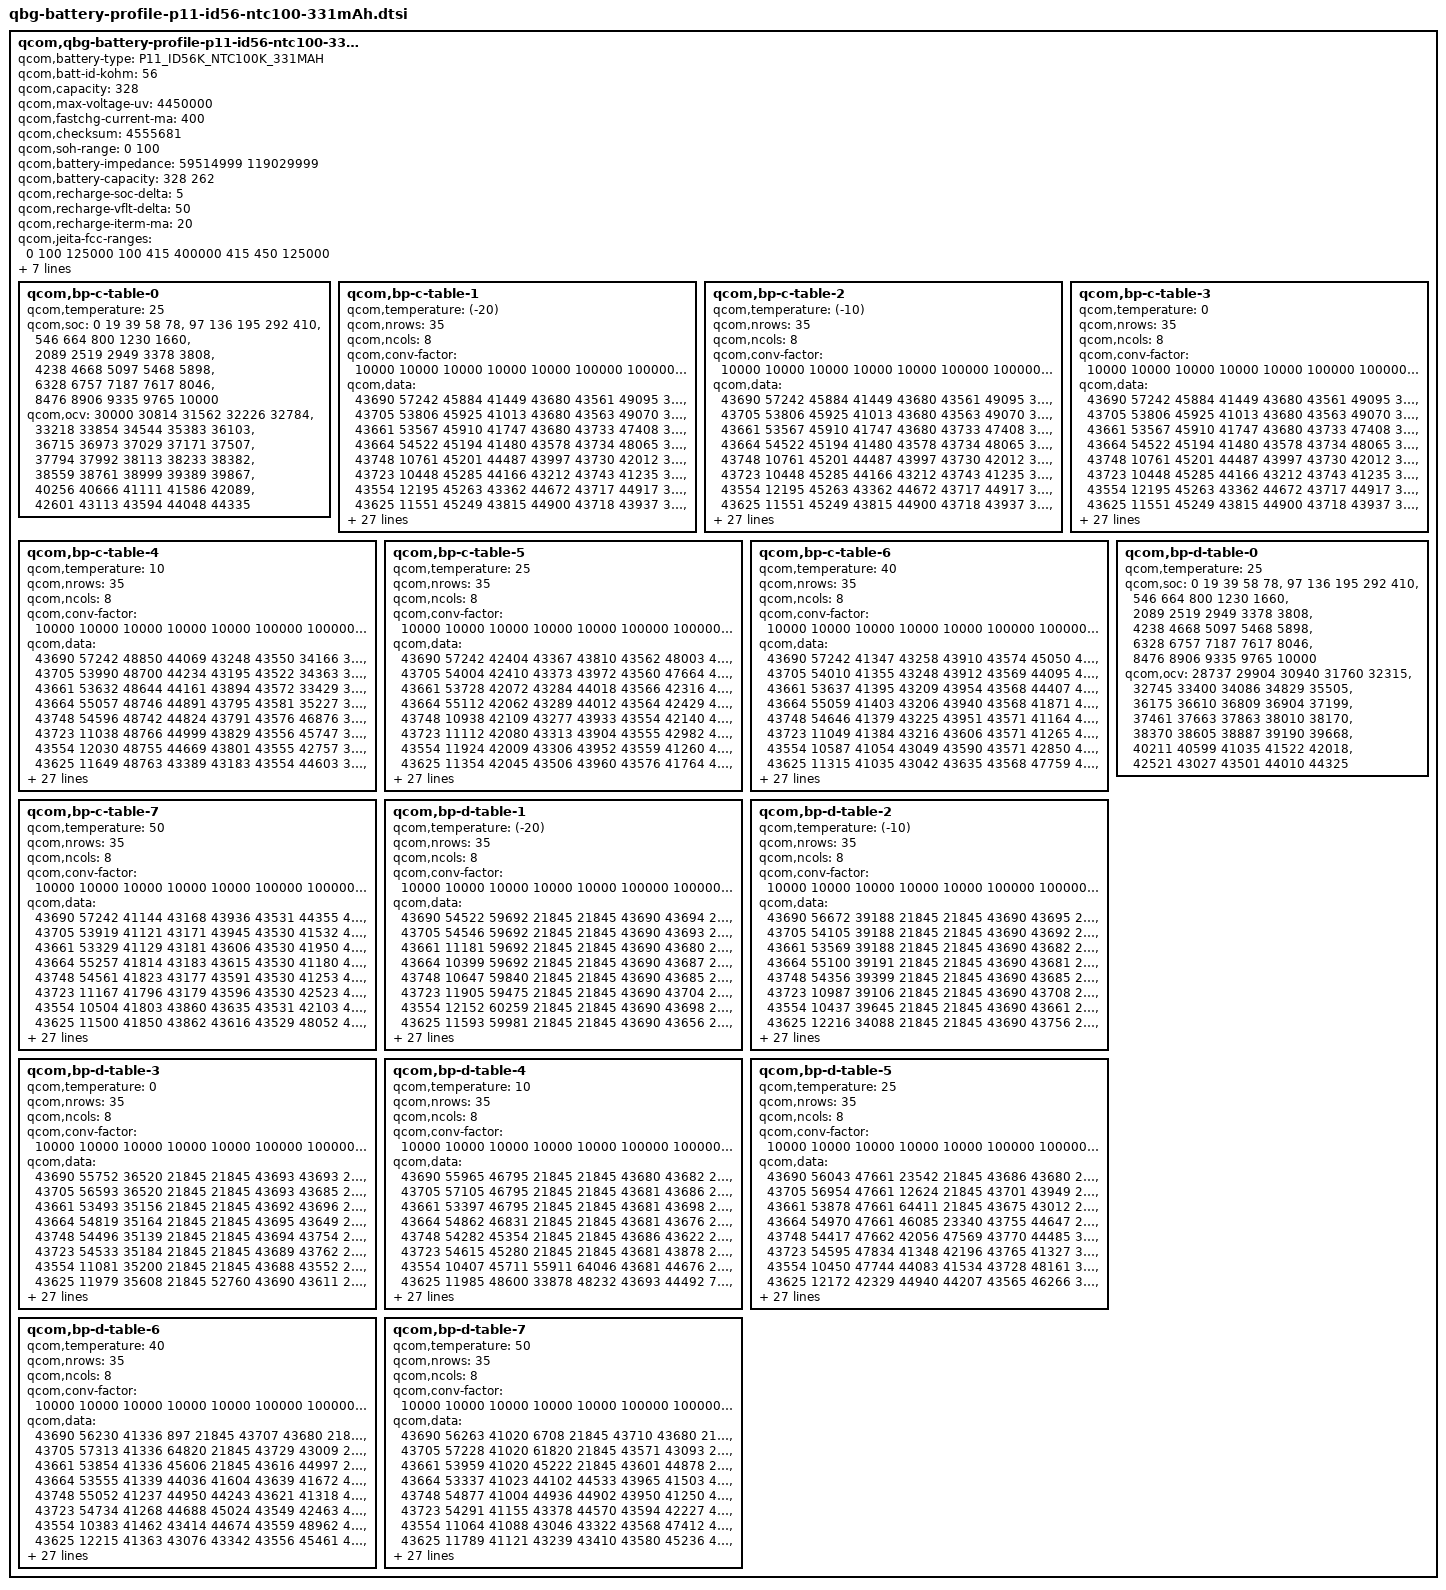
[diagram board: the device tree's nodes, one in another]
// SPDX-License-Identifier: GPL-2.0

/*QBG Profiling Rev. 2.7*/

qcom,qbg-battery-profile-p11-id56-ntc100-331mAh {
	qcom,battery-type = "P11_ID56K_NTC100K_331MAH";
	qcom,batt-id-kohm = <56>;
	/* 331 is the capacity of the cell, the minimum capacity is 328 mAh because
	of losing some usable capacity by PCM */
	qcom,capacity = <328>;

	qcom,max-voltage-uv = <4450000>;
	qcom,fastchg-current-ma = <400>;
	/*@5, 0.005V, 4% */
	qcom,checksum = <4555681>;
	qcom,soh-range = <0 100>;
	/* Nominal_Impedance in 10nohm @ SOC 50% 25C* 0:fresh cell, 1: aged cell */
	qcom,battery-impedance = <59514999 119029999>;
	/* Nominal_Capacity in mAh. 0: fresh cell, 1:aged cell */
	/* 100% 80% */
	qcom,battery-capacity = <328 262>;
	/* SOC delta (in percent) dropped from EOC SOC to enable recharge */
	qcom,recharge-soc-delta =<5>;
	/* vfloat delta (in mV) dropped from regular vfloat in recharge */
	qcom,recharge-vflt-delta =<50>;
	/* termination current (in mA) in recharge */
	qcom,recharge-iterm-ma = <20>;
	/* LowTemp HighTemp CharingCurrent (uA) */
	qcom,jeita-fcc-ranges = <0  100 125000
				100 415 400000
				415 450 125000>;

	qcom,jeita-fv-ranges = <0   100 4450000
				100 415 4450000
				415 450 4450000>;

	/* COOL = 10 DegC, WARM = 41.5 DegC */
	qcom,jeita-soft-thresholds = <0x2b8a 0x1491>;
	/* COLD = 0 DegC, HOT = 45 DegC */
	qcom,jeita-hard-thresholds = <0x3257 0x128c>;
	/* COOL = 12 DegC, WARM = 39.5 DegC*/
	qcom,jeita-soft-hys-thresholds = <0x2a0b 0x15ca>;
	qcom,jeita-soft-fcc-ua = <125000 125000>;
	qcom,jeita-soft-fv-uv = <4450000 4450000>;

	qcom,bp-c-table-0 {
		qcom,temperature = <25>;
		qcom,soc = <    0    19    39    58    78>,
			<   97   136   195   292   410>,
			<  546   664   800  1230  1660>,
			< 2089  2519  2949  3378  3808>,
			< 4238  4668  5097  5468  5898>,
			< 6328  6757  7187  7617  8046>,
			< 8476  8906  9335  9765 10000>;
		qcom,ocv = <30000 30814 31562 32226 32784>,
			<33218 33854 34544 35383 36103>,
			<36715 36973 37029 37171 37507>,
			<37794 37992 38113 38233 38382>,
			<38559 38761 38999 39389 39867>,
			<40256 40666 41111 41586 42089>,
			<42601 43113 43594 44048 44335>;
	};
	qcom,bp-c-table-1 {
		qcom,temperature = <(-20)>;
		qcom,nrows = <35>;
		qcom,ncols = <8>;
		qcom,conv-factor = <10000 10000 10000 10000 10000 100000 100000 10000>;
		qcom,data = <43690 57242 45884 41449 43680 43561 49095 39200>,
			<43705 53806 45925 41013 43680 43563 49070 38997>,
			<43661 53567 45910 41747 43680 43733 47408 39105>,
			<43664 54522 45194 41480 43578 43734 48065 39800>,
			<43748 10761 45201 44487 43997 43730 42012 39827>,
			<43723 10448 45285 44166 43212 43743 41235 39432>,
			<43554 12195 45263 43362 44672 43717 44917 34086>,
			<43625 11551 45249 43815 44900 43718 43937 33994>,
			<43918  8286 45242 43547 44237 43742 43623 34770>,
			<43824 10002 45907 43838 44998 43556 43955 34428>,
			<43144 15012 45243 43543 44885 43577 43637 34435>,
			<43058 14969 45939 44010 45012 43531 43950 33148>,
			<43402 15271 45897 43789 44929 43530 43909 33028>,
			<44644 15135 45937 44387 43171 43553 47659 33975>,
			<44246 14759 45184 41786 43134 43729 47879 34058>,
			<41603 16030 45478 41114 43465 43731 48066 34120>,
			<41853 16299 45876 40986 43291 43730 47836 39585>,
			<41263 16328 46057 41378 43355 43741 47741 39570>,
			<42904 16236 46057 41466 44682 43743 47794 39469>,
			<42058 15509 46024 41258 44749 43737 41993 39514>,
			<47652 15470 46075 41318 44655 43739 42381 39891>,
			<47254 15856 46055 42727 44625 43736 47587 39098>,
			<47427 13051 46066 42558 44553 43737 48295 39796>,
			<49142 13073 46030 42554 43283 43736 48821 39502>,
			<48544 12746 46045 42628 44678 43713 44380 39830>,
			<45586 13853 45220 42998 44544 43724 41562 39183>,
			<45263 13567 45089 42877 44989 43720 44424 40756>,
			<46777 13650 45448 42193 44902 43765 44193 37536>,
			<46955  2820 45318 42405 44117 43765 44952 37284>,
			<46532  2350 46774 42481 41545 43765 44683 37912>,
			<35766  4036 46624 42273 41323 43720 43506 59866>,
			<34912  3535 47011 42345 47786 43727 43109 57510>,
			<36573  1023 46969 42445 48610 43715 43258 63817>,
			<35983   433 46933 42825 36753 43721 43890 51539>,
			<36282  1773 46140 44923 47301 43617 43647 59129>;
	};
	qcom,bp-c-table-2 {
		qcom,temperature = <(-10)>;
		qcom,nrows = <35>;
		qcom,ncols = <8>;
		qcom,conv-factor = <10000 10000 10000 10000 10000 100000 100000 10000>;
		qcom,data = <43690 57242 45884 41449 43680 43561 49095 39200>,
			<43705 53806 45925 41013 43680 43563 49070 38997>,
			<43661 53567 45910 41747 43680 43733 47408 39105>,
			<43664 54522 45194 41480 43578 43734 48065 39800>,
			<43748 10761 45201 44487 43997 43730 42012 39827>,
			<43723 10448 45285 44166 43212 43743 41235 39432>,
			<43554 12195 45263 43362 44672 43717 44917 34086>,
			<43625 11551 45249 43815 44900 43718 43937 33994>,
			<43918  8286 45242 43547 44237 43742 43623 34770>,
			<43824 10002 45907 43838 44998 43556 43955 34428>,
			<43144 15012 45243 43543 44885 43577 43637 34435>,
			<43058 14969 45939 44010 45012 43531 43950 33148>,
			<43402 15271 45897 43789 44929 43530 43909 33028>,
			<44644 15135 45937 44387 43171 43553 47659 33975>,
			<44246 14759 45184 41786 43134 43729 47879 34058>,
			<41603 16030 45478 41114 43465 43731 48066 34120>,
			<41853 16299 45876 40986 43291 43730 47836 39585>,
			<41263 16328 46057 41378 43355 43741 47741 39570>,
			<42904 16236 46057 41466 44682 43743 47794 39469>,
			<42058 15509 46024 41258 44749 43737 41993 39514>,
			<47652 15470 46075 41318 44655 43739 42381 39891>,
			<47254 15856 46055 42727 44625 43736 47587 39098>,
			<47427 13051 46066 42558 44553 43737 48295 39796>,
			<49142 13073 46030 42554 43283 43736 48821 39502>,
			<48544 12746 46045 42628 44678 43713 44380 39830>,
			<45586 13853 45220 42998 44544 43724 41562 39183>,
			<45263 13567 45089 42877 44989 43720 44424 40756>,
			<46777 13650 45448 42193 44902 43765 44193 37536>,
			<46955  2820 45318 42405 44117 43765 44952 37284>,
			<46532  2350 46774 42481 41545 43765 44683 37912>,
			<35766  4036 46624 42273 41323 43720 43506 59866>,
			<34912  3535 47011 42345 47786 43727 43109 57510>,
			<36573  1023 46969 42445 48610 43715 43258 63817>,
			<35983   433 46933 42825 36753 43721 43890 51539>,
			<36282  1773 46140 44923 47301 43617 43647 59129>;
	};
	qcom,bp-c-table-3 {
		qcom,temperature = <0>;
		qcom,nrows = <35>;
		qcom,ncols = <8>;
		qcom,conv-factor = <10000 10000 10000 10000 10000 100000 100000 10000>;
		qcom,data = <43690 57242 45884 41449 43680 43561 49095 39200>,
			<43705 53806 45925 41013 43680 43563 49070 38997>,
			<43661 53567 45910 41747 43680 43733 47408 39105>,
			<43664 54522 45194 41480 43578 43734 48065 39800>,
			<43748 10761 45201 44487 43997 43730 42012 39827>,
			<43723 10448 45285 44166 43212 43743 41235 39432>,
			<43554 12195 45263 43362 44672 43717 44917 34086>,
			<43625 11551 45249 43815 44900 43718 43937 33994>,
			<43918  8286 45242 43547 44237 43742 43623 34770>,
			<43824 10002 45907 43838 44998 43556 43955 34428>,
			<43144 15012 45243 43543 44885 43577 43637 34435>,
			<43058 14969 45939 44010 45012 43531 43950 33148>,
			<43402 15271 45897 43789 44929 43530 43909 33028>,
			<44644 15135 45937 44387 43171 43553 47659 33975>,
			<44246 14759 45184 41786 43134 43729 47879 34058>,
			<41603 16030 45478 41114 43465 43731 48066 34120>,
			<41853 16299 45876 40986 43291 43730 47836 39585>,
			<41263 16328 46057 41378 43355 43741 47741 39570>,
			<42904 16236 46057 41466 44682 43743 47794 39469>,
			<42058 15509 46024 41258 44749 43737 41993 39514>,
			<47652 15470 46075 41318 44655 43739 42381 39891>,
			<47254 15856 46055 42727 44625 43736 47587 39098>,
			<47427 13051 46066 42558 44553 43737 48295 39796>,
			<49142 13073 46030 42554 43283 43736 48821 39502>,
			<48544 12746 46045 42628 44678 43713 44380 39830>,
			<45586 13853 45220 42998 44544 43724 41562 39183>,
			<45263 13567 45089 42877 44989 43720 44424 40756>,
			<46777 13650 45448 42193 44902 43765 44193 37536>,
			<46955  2820 45318 42405 44117 43765 44952 37284>,
			<46532  2350 46774 42481 41545 43765 44683 37912>,
			<35766  4036 46624 42273 41323 43720 43506 59866>,
			<34912  3535 47011 42345 47786 43727 43109 57510>,
			<36573  1023 46969 42445 48610 43715 43258 63817>,
			<35983   433 46933 42825 36753 43721 43890 51539>,
			<36282  1773 46140 44923 47301 43617 43647 59129>;
	};
	qcom,bp-c-table-4 {
		qcom,temperature = <10>;
		qcom,nrows = <35>;
		qcom,ncols = <8>;
		qcom,conv-factor = <10000 10000 10000 10000 10000 100000 100000 10000>;
		qcom,data = <43690 57242 48850 44069 43248 43550 34166 36741>,
			<43705 53990 48700 44234 43195 43522 34363 36356>,
			<43661 53632 48644 44161 43894 43572 33429 36482>,
			<43664 55057 48746 44891 43795 43581 35227 35125>,
			<43748 54596 48742 44824 43791 43576 46876 35260>,
			<43723 11038 48766 44999 43829 43556 45747 34874>,
			<43554 12030 48755 44669 43801 43555 42757 35639>,
			<43625 11649 48763 43389 43183 43554 44603 35376>,
			<43918  8237 48851 43849 43374 43526 43982 46439>,
			<43824 10227 48788 43103 43041 43532 43416 46588>,
			<43144  9492 48774 43465 43858 43529 44590 46182>,
			<43058 14862 47442 43208 43076 43550 43840 46278>,
			<43402 14974 48807 43393 43243 43535 45037 46275>,
			<44644 15296 48814 44204 43894 43554 42249 35526>,
			<44246 14447 47364 44105 43069 43733 42194 35815>,
			<41603 14659 47395 44515 43436 43733 42002 35641>,
			<41853 15898 47603 44291 43394 43735 42267 35585>,
			<41263 16306 47513 44412 43498 43735 42354 35596>,
			<42904 16340 47524 41634 43515 43735 42433 35612>,
			<42058 15527 47512 41635 43314 43729 41216 35651>,
			<47652 15363 47523 41659 44727 43728 41211 35062>,
			<47254 15857 47531 41618 44598 43730 41416 34935>,
			<47427 12931 47183 41583 44559 43731 47497 35324>,
			<49142 13275 47219 41596 44719 43728 47386 34842>,
			<48544 12554 47229 41697 43105 43740 41751 35453>,
			<45586 14268 47212 41655 43517 43742 44452 35722>,
			<45263 13336 47192 41481 43412 43739 44438 35584>,
			<46777  2802 47197 41931 43302 43718 44137 34898>,
			<46955  2188 47506 41126 44747 43715 44839 36469>,
			<46532  3748 47393 41001 44861 43715 44578 36227>,
			<35766  3235 47439 41073 44490 43713 43368 32952>,
			<34912   674 48880 41050 41198 43717 43402 33920>,
			<36573   856 48662 40976 47801 43743 43048 40528>,
			<35983   284 49077 41530 42499 43742 43406 39518>,
			<36282  1559 49136 44147 47896 43718 43799 40944>;
	};
	qcom,bp-c-table-5 {
		qcom,temperature = <25>;
		qcom,nrows = <35>;
		qcom,ncols = <8>;
		qcom,conv-factor = <10000 10000 10000 10000 10000 100000 100000 10000>;
		qcom,data = <43690 57242 42404 43367 43810 43562 48003 48160>,
			<43705 54004 42410 43373 43972 43560 47664 48381>,
			<43661 53728 42072 43284 44018 43566 42316 48270>,
			<43664 55112 42062 43289 44012 43564 42429 48987>,
			<43748 10938 42109 43277 43933 43554 42140 48917>,
			<43723 11112 42080 43313 43904 43555 42982 48933>,
			<43554 11924 42009 43306 43952 43559 41260 49042>,
			<43625 11354 42045 43506 43960 43576 41764 48764>,
			<43918  8349 42204 43454 43934 43571 44512 48860>,
			<43824 10157 42239 43111 43982 43528 44810 48777>,
			<43144  9665 42131 43069 43998 43520 44842 47460>,
			<43058 15047 42121 43132 43590 43573 41290 47554>,
			<43402 14863 42169 43121 43608 43572 42648 47602>,
			<44644 15257 42155 43323 43148 43577 44415 49026>,
			<44246 14377 42863 43356 43016 43576 41720 48995>,
			<41603 14600 42800 44776 43032 43577 41057 48966>,
			<41853 16066 42966 44740 43052 43578 42511 48992>,
			<41263 15947 42956 44581 43217 43557 42921 49001>,
			<42904 16371 42988 44561 43055 43578 41330 48962>,
			<42058 16196 42881 44580 43395 43579 44514 48284>,
			<47652 15413 42928 44725 44732 43552 45018 48177>,
			<47254 15811 42914 44798 44746 43566 44111 48557>,
			<47427 13053 42585 44635 44672 43559 42608 48609>,
			<49142 13175 42573 44646 43094 43558 41404 48293>,
			<48544 12561 42614 44607 43251 43554 44489 49086>,
			<45586 14314 42596 44595 43215 43567 44867 49076>,
			<45263 13424 42604 44669 43061 43560 44933 48956>,
			<46777  2621 42593 45039 43126 43562 44622 48382>,
			<46955  2264 42596 44917 43450 43735 44978 48536>,
			<46532  3779 42610 44226 43315 43734 44758 45810>,
			<35766  3267 42579 44518 44648 43731 44704 45113>,
			<34912   707 42910 44532 44072 43732 43482 46612>,
			<36573   224 42950 44424 41820 43558 43130 35504>,
			<35983  1722 42858 44991 44533 43558 43468 45387>,
			<36282  1925 42858 44727 41269 43561 43897 46488>;
	};
	qcom,bp-c-table-6 {
		qcom,temperature = <40>;
		qcom,nrows = <35>;
		qcom,ncols = <8>;
		qcom,conv-factor = <10000 10000 10000 10000 10000 100000 100000 10000>;
		qcom,data = <43690 57242 41347 43258 43910 43574 45050 42259>,
			<43705 54010 41355 43248 43912 43569 44095 42246>,
			<43661 53637 41395 43209 43954 43568 44407 42292>,
			<43664 55059 41403 43206 43940 43568 41871 42299>,
			<43748 54646 41379 43225 43951 43571 41164 42281>,
			<43723 11049 41384 43216 43606 43571 41265 42463>,
			<43554 10587 41054 43049 43590 43571 42850 42483>,
			<43625 11315 41035 43042 43635 43568 47759 42373>,
			<43918  9078 41058 43216 43631 43530 47271 42049>,
			<43824  9729 40989 43226 43624 43533 48075 42094>,
			<43144  9636 40973 43247 43620 43551 42840 42018>,
			<43058 15004 41013 43780 43633 43630 41179 42817>,
			<43402 15065 41008 43805 43634 43626 41267 42843>,
			<44644 14916 40995 43145 43184 43549 44938 42243>,
			<44246 14493 41169 43233 43239 43551 44926 42320>,
			<41603 14821 41178 43211 43252 43545 44510 47803>,
			<41853 16061 41166 43231 43149 43521 41836 42310>,
			<41263 15876 41209 43051 43901 43534 41133 42255>,
			<42904 16272 41192 43110 43878 43572 41930 42359>,
			<42058 16240 41114 43075 43260 43522 44917 47813>,
			<47652 15413 41096 43890 43378 43544 43435 47717>,
			<47254 15838 41144 43193 44704 43529 44738 48004>,
			<47427 13022 41133 43045 43371 43528 41607 48111>,
			<49142 13141 41815 43017 43232 43531 41907 42324>,
			<48544 12649 41811 43045 43778 43530 44295 42374>,
			<45586 14328 41823 43045 43804 43572 44837 42473>,
			<45263 13400 41797 43110 43178 43571 44567 42367>,
			<46777  2578 41799 43444 43260 43578 44775 47649>,
			<46955  2102 41798 43476 43011 43555 44685 48103>,
			<46532  3641 41818 43346 43081 43565 44792 47288>,
			<35766  3131 41809 44570 43438 43559 44964 47520>,
			<34912   547 41121 44960 44681 43578 44775 48696>,
			<36573   245 41141 44671 44892 43531 43315 48261>,
			<35983  1689 41111 43117 44581 43572 43096 47130>,
			<36282  1992 41144 43056 44514 43531 43183 49037>;
	};
	qcom,bp-c-table-7 {
		qcom,temperature = <50>;
		qcom,nrows = <35>;
		qcom,ncols = <8>;
		qcom,conv-factor = <10000 10000 10000 10000 10000 100000 100000 10000>;
		qcom,data = <43690 57242 41144 43168 43936 43531 44355 42123>,
			<43705 53919 41121 43171 43945 43530 41532 42148>,
			<43661 53329 41129 43181 43606 43530 41950 42833>,
			<43664 55257 41814 43183 43615 43530 41180 42818>,
			<43748 54561 41823 43177 43591 43530 41253 42879>,
			<43723 11167 41796 43179 43596 43530 42523 42862>,
			<43554 10504 41803 43860 43635 43531 42103 42761>,
			<43625 11500 41850 43862 43616 43529 48052 42966>,
			<43918  8995 41750 43857 43536 43523 47539 42980>,
			<43824  9983 41733 43859 43520 43527 48643 42893>,
			<43144  9247 41736 43865 43530 43536 48971 42922>,
			<43058  9555 41780 43911 43640 43587 44391 42747>,
			<43402 14993 41779 43924 43643 43638 41777 42737>,
			<44644 14855 41787 43800 43888 43623 44544 42820>,
			<44246 15199 41763 43872 43846 43620 45043 42169>,
			<41603 14757 41770 43881 43191 43621 44890 42117>,
			<41853 14664 41948 43792 43177 43622 44303 42157>,
			<41263 15908 41926 43878 43815 43625 41562 42778>,
			<42904 16258 41973 43170 43989 43545 41678 42873>,
			<42058 16228 41982 43261 43896 43551 44276 42198>,
			<47652 15411 41965 43996 43412 43634 43112 42061>,
			<47254 15824 41878 44000 43373 43628 43459 42398>,
			<47427 12846 41881 43777 43477 43537 44259 42388>,
			<49142 12455 41863 43843 43871 43542 41954 42157>,
			<48544 12640 41858 43874 43994 43536 44524 42984>,
			<45586 14326 41870 43882 43821 43551 44563 42997>,
			<45263 13738 41909 43861 43879 43527 44798 42840>,
			<46777  2658 41904 43255 43183 43529 44747 42035>,
			<46955  2054 41907 43115 43158 43568 44601 42391>,
			<46532  3593 41904 43449 43205 43583 44566 42360>,
			<35766  3083 41908 43511 43035 43576 44645 47820>,
			<34912   549 41870 44719 43411 43569 44940 47879>,
			<36573   244 41882 43359 44744 43546 44599 47212>,
			<35983  1692 41876 43257 43475 43544 43320 47794>,
			<36282  1988 41553 43258 44274 43520 43219 47204>;
	};
	qcom,bp-d-table-0 {
		qcom,temperature = <25>;
		qcom,soc = <    0    19    39    58    78>,
			<   97   136   195   292   410>,
			<  546   664   800  1230  1660>,
			< 2089  2519  2949  3378  3808>,
			< 4238  4668  5097  5468  5898>,
			< 6328  6757  7187  7617  8046>,
			< 8476  8906  9335  9765 10000>;
		qcom,ocv = <28737 29904 30940 31760 32315>,
			<32745 33400 34086 34829 35505>,
			<36175 36610 36809 36904 37199>,
			<37461 37663 37863 38010 38170>,
			<38370 38605 38887 39190 39668>,
			<40211 40599 41035 41522 42018>,
			<42521 43027 43501 44010 44325>;
	};
	qcom,bp-d-table-1 {
		qcom,temperature = <(-20)>;
		qcom,nrows = <35>;
		qcom,ncols = <8>;
		qcom,conv-factor = <10000 10000 10000 10000 10000 100000 100000 10000>;
		qcom,data = <43690 54522 59692 21845 21845 43690 43694 21845>,
			<43705 54546 59692 21845 21845 43690 43693 21845>,
			<43661 11181 59692 21845 21845 43690 43680 21845>,
			<43664 10399 59692 21845 21845 43690 43687 21845>,
			<43748 10647 59840 21845 21845 43690 43685 21845>,
			<43723 11905 59475 21845 21845 43690 43704 21845>,
			<43554 12152 60259 21845 21845 43690 43698 21845>,
			<43625 11593 59981 21845 21845 43690 43656 21845>,
			<43918  8237 38246 21845  1141 43690 43669 21845>,
			<43824  9783 38070 21845 62824 43690 43564 21845>,
			<43144 10055 37123 21845 37330 43690 43594 21845>,
			<43058  9266 36994 21845 33190 43690 43934 21845>,
			<43402  9610 37459 21845 35522 43690 43818 21845>,
			<44644 15088 40497 12262 47246 43691 43205 21845>,
			<44246 15246 39244 57086 46059 43691 43115 21845>,
			<41603 15226 39023 64534 48357 43688 43424 21845>,
			<41853 14529 39531 59628 47945 43689 43515 22790>,
			<41263 14764 34144 40597 42168 43689 43278 30745>,
			<42904 14593 34288 33168 41318 43694 43376  5671>,
			<42058 16113 34639 36466 40967 43695 43366  1537>,
			<47652 16307 34786 35471 41830 43695 43377 13624>,
			<47254 16200 34660 46807 41957 43692 43369 16361>,
			<47427 15377 34447 45205 41507 43693 44728  8561>,
			<49142 15663 34543 45625 44385 43682 44583 11800>,
			<48544 12836 33115 48445 44033 43683 44921 54431>,
			<45586 13173 33262 48542 44223 43681 41484 54227>,
			<45263 12605 33201 48196 44166 43686 41437 56336>,
			<46777 14100 32861 48239 44498 43687 42755 56470>,
			<46955  2768 33191 45707 41934 43684 48730 54033>,
			<46532  2231 33167 48521 41158 43685 41254 54025>,
			<35766  3761 32838 48507 41168 43706 41103 53424>,
			<34912  3278 33201 48415 41121 43674 41248 53371>,
			<36573   539 33053 48458 41883 43650 41140 54127>,
			<35983   469 34416 45571 44360 43690 44699 56450>,
			<36282  1996 34811 45966 44501 43690 43707 57028>;
	};
	qcom,bp-d-table-2 {
		qcom,temperature = <(-10)>;
		qcom,nrows = <35>;
		qcom,ncols = <8>;
		qcom,conv-factor = <10000 10000 10000 10000 10000 100000 100000 10000>;
		qcom,data = <43690 56672 39188 21845 21845 43690 43695 21845>,
			<43705 54105 39188 21845 21845 43690 43692 21845>,
			<43661 53569 39188 21845 21845 43690 43682 21845>,
			<43664 55100 39191 21845 21845 43690 43681 21845>,
			<43748 54356 39399 21845 21845 43690 43685 21845>,
			<43723 10987 39106 21845 21845 43690 43708 21845>,
			<43554 10437 39645 21845 21845 43690 43661 21845>,
			<43625 12216 34088 21845 21845 43690 43756 21845>,
			<43918  8920 34218 21845 64886 43690 43578 21845>,
			<43824  8506 34719 21845 35504 43690 43931 21845>,
			<43144  9389 33051  2485 47312 43690 43243 21845>,
			<43058  9663 33291 51380 42843 43691 43510 21845>,
			<43402  9535 33423 38196 41113 43691 44725 16436>,
			<44644 14861 36355 45310 44925 43694 44863  9310>,
			<44246 15321 35147 45505 41635 43695 44982 11400>,
			<41603 14501 35052 48192 44129 43682 44919 55599>,
			<41853 14387 35731 47119 45044 43686 44227 52796>,
			<41263 14732 35395 42377 44754 43705 44106 61872>,
			<42904 14620 35403 42935 44730 43657 44126 64641>,
			<42058 16103 35340 41294 43427 43765 41973 63739>,
			<47652 15953 35373 41258 43101 43727 41777 58835>,
			<47254 16224 35413 41467 43426 43715 41089 59191>,
			<47427 15776 35762 41300 43399 43739 49056 59162>,
			<49142 13029 35768 42744 43284 43740 48243 58534>,
			<48544 13178 35418 42530 44602 43730 48858 58424>,
			<45586 12583 35405 42914 45055 43734 47592 58824>,
			<45263 14105 35760 42854 44138 43563 48976 64069>,
			<46777 13616 35345 42844 44392 43731 42822 64316>,
			<46955  3009 35434 42490 44469 43729 42879 64346>,
			<46532  2519 35392 47771 44519 43738 42846 63594>,
			<35766  3881 35426 47640 44328 43725 42569 63939>,
			<34912  3371 35431 47708 44333 43726 41219 63754>,
			<36573   973 35430 47643 44156 43764 41799 63910>,
			<35983   278 35430 42241 44609 43774 44510 64404>,
			<36282  2038 35450 42378 44760 43748 44881 64050>;
	};
	qcom,bp-d-table-3 {
		qcom,temperature = <0>;
		qcom,nrows = <35>;
		qcom,ncols = <8>;
		qcom,conv-factor = <10000 10000 10000 10000 10000 100000 100000 10000>;
		qcom,data = <43690 55752 36520 21845 21845 43693 43693 21845>,
			<43705 56593 36520 21845 21845 43693 43685 21845>,
			<43661 53493 35156 21845 21845 43692 43696 21845>,
			<43664 54819 35164 21845 21845 43695 43649 21845>,
			<43748 54496 35139 21845 21845 43694 43754 21845>,
			<43723 54533 35184 21845 21845 43689 43762 21845>,
			<43554 11081 35200 21845 21845 43688 43552 21845>,
			<43625 11979 35608 21845 52760 43690 43611 21845>,
			<43918 11639 35491  7003 46716 43690 43186 21845>,
			<43824  8611 46110 57989 41076 43691 43513 23808>,
			<43144 10059 47046 46526 44217 43688 44836 13345>,
			<43058  9628 46604 48677 44637 43689 44461 55168>,
			<43402  9477 45406 42409 43476 43692 41676 53222>,
			<44644 15098 45127 41521 43057 43707 44513 58307>,
			<44246 15296 45102 41773 43010 43669 42210 60674>,
			<41603 14392 45843 41739 43407 43712 45856 59839>,
			<41853 14727 45864 41968 43415 43717 45712 37919>,
			<41263 14626 45861 41599 43130 43737 48079 36983>,
			<42904 14670 45873 41710 43047 43742 41224 40241>,
			<42058 16069 46030 41658 43263 43730 41073 40897>,
			<47652 16330 45839 41482 43256 43733 45803 40538>,
			<47254 15571 45857 41490 43085 43560 48444 40565>,
			<47427 15669 45834 41594 43461 43561 47527 40573>,
			<49142 12910 45827 41891 43331 43566 47844 40867>,
			<48544 12527 45934 41769 44791 43566 42021 40767>,
			<45586 13985 45925 41148 44961 43560 42963 40137>,
			<45263 13449 45856 40990 44161 43732 42549 40226>,
			<46777 13658 45867 41410 44215 43734 41803 40220>,
			<46955  2902 46041 42731 44265 43738 41059 37413>,
			<46532  2382 45869 42739 44233 43712 41571 37818>,
			<35766  3918 46031 42506 44281 43724 41504 37848>,
			<34912  3403 46064 42568 44212 43714 41539 37660>,
			<36573   791 46048 42517 45041 43724 41963 37866>,
			<35983   332 45978 42687 43388 43722 41971 40193>,
			<36282  2045 45963 41227 43440 43766 41878 40362>;
	};
	qcom,bp-d-table-4 {
		qcom,temperature = <10>;
		qcom,nrows = <35>;
		qcom,ncols = <8>;
		qcom,conv-factor = <10000 10000 10000 10000 10000 100000 100000 10000>;
		qcom,data = <43690 55965 46795 21845 21845 43680 43682 21845>,
			<43705 57105 46795 21845 21845 43681 43686 21845>,
			<43661 53397 46795 21845 21845 43681 43698 21845>,
			<43664 54862 46831 21845 21845 43681 43676 21845>,
			<43748 54282 45354 21845 21845 43686 43622 21845>,
			<43723 54615 45280 21845 21845 43681 43878 21845>,
			<43554 10407 45711 55911 64046 43681 44676 21845>,
			<43625 11985 48600 33878 48232 43693 44492  7036>,
			<43918 11569 48150 48348 44349 43695 41437 57306>,
			<43824  8247 48968 41243 43517 43681 41238 64499>,
			<43144 10176 49094 44527 43059 43660 41254 38184>,
			<43058  9645 49127 44268 43014 43753 41036 37869>,
			<43402  9476 49045 44871 43249 43765 41060 40875>,
			<44644 15001 49082 44974 43992 43735 42888 33237>,
			<44246 15301 48679 44185 43244 43741 42845 33275>,
			<41603 14549 48788 44273 43102 43562 42776 33361>,
			<41853 14726 47442 44235 43424 43565 42203 35843>,
			<41263 14643 47486 44179 43046 43555 42011 36565>,
			<42904 16048 47425 44164 43156 43552 47706 35255>,
			<42058 15967 47381 44279 43041 43558 48362 34909>,
			<47652 16149 47438 44270 43031 43559 48002 34849>,
			<47254 15373 47384 44263 43133 43559 42795 34998>,
			<47427 15727 47362 44246 43093 43559 42736 34993>,
			<49142 12891 47362 44142 43409 43558 42677 35071>,
			<48544 12345 47371 44513 43267 43552 42563 35202>,
			<45586 13866 47392 41641 44799 43553 42238 36546>,
			<45263 13345 47583 41513 44969 43553 42934 36803>,
			<46777  2800 47563 41548 44628 43563 41349 36729>,
			<46955  2180 47578 41490 44928 43729 44380 36701>,
			<46532  3723 47555 41917 44645 43734 44382 35989>,
			<35766  3254 47392 41953 44580 43731 41635 35885>,
			<34912   700 47414 41975 44762 43741 41515 35930>,
			<36573   845 47375 41858 44729 43742 41568 35962>,
			<35983   347 47379 41518 43501 43717 41493 36674>,
			<36282  2025 47380 41628 43096 43716 41663 36737>;
	};
	qcom,bp-d-table-5 {
		qcom,temperature = <25>;
		qcom,nrows = <35>;
		qcom,ncols = <8>;
		qcom,conv-factor = <10000 10000 10000 10000 10000 100000 100000 10000>;
		qcom,data = <43690 56043 47661 23542 21845 43686 43680 21845>,
			<43705 56954 47661 12624 21845 43701 43949 21845>,
			<43661 53878 47661 64411 21845 43675 43012 21845>,
			<43664 54970 47661 46085 23340 43755 44647 21845>,
			<43748 54417 47662 42056 47569 43770 44485 38596>,
			<43723 54595 47834 41348 42196 43765 41327 39696>,
			<43554 10450 47744 44083 41534 43728 48161 36436>,
			<43625 12172 42329 44940 44207 43565 46266 35475>,
			<43918  8871 42337 44565 44693 43559 35483 46855>,
			<43824  8219 42253 44741 43238 43576 46788 45173>,
			<43144 10213 42487 43349 43822 43583 47388 45670>,
			<43058  9640 42474 44715 43887 43582 41255 45603>,
			<43402  9571 42379 44730 43802 43573 41268 45757>,
			<44644 14978 42105 43089 43950 43579 42699 49055>,
			<44246 15333 41990 43274 43890 43577 41212 48334>,
			<41603 14591 42137 43280 43208 43581 41938 48275>,
			<41853 14773 42154 43283 43037 43531 41098 48310>,
			<41263 14669 42878 44730 43076 43546 42437 48328>,
			<42904 16080 42779 43286 43394 43532 41039 48290>,
			<42058 16304 42786 43325 43094 43533 41531 49110>,
			<47652 16200 42949 43364 43042 43522 41765 49083>,
			<47254 15463 43002 43341 43167 43534 41140 48665>,
			<47427 15693 42906 43328 43163 43573 41145 48676>,
			<49142 13244 42890 44718 43259 43572 41002 48656>,
			<48544 12382 42939 44603 43442 43534 41995 48290>,
			<45586 14265 42579 44973 44728 43526 47191 48591>,
			<45263 13373 42562 44565 44721 43581 41147 48563>,
			<46777  2785 42574 44589 44731 43557 44119 48253>,
			<46955  2200 42561 44617 43322 43571 44424 48230>,
			<46532  3720 42579 45053 43134 43574 41622 48137>,
			<35766  3251 42938 45025 43051 43580 44413 48333>,
			<34912   697 42882 44945 43156 43576 41557 48276>,
			<36573   839 42978 44966 43147 43576 41128 48303>,
			<35983   320 42969 44558 43171 43580 41411 48902>,
			<36282  1935 42790 44754 43857 43571 42663 49107>;
	};
	qcom,bp-d-table-6 {
		qcom,temperature = <40>;
		qcom,nrows = <35>;
		qcom,ncols = <8>;
		qcom,conv-factor = <10000 10000 10000 10000 10000 100000 100000 10000>;
		qcom,data = <43690 56230 41336   897 21845 43707 43680 21845>,
			<43705 57313 41336 64820 21845 43729 43009 21845>,
			<43661 53854 41336 45606 21845 43616 44997 21845>,
			<43664 53555 41339 44036 41604 43639 41672 47015>,
			<43748 55052 41237 44950 44243 43621 41318 45971>,
			<43723 54734 41268 44688 45024 43549 42463 48191>,
			<43554 10383 41462 43414 44674 43559 48962 48814>,
			<43625 12215 41363 43076 43342 43556 45461 47507>,
			<43918  8954 41404 43130 43463 43582 35591 47310>,
			<43824  8292 41047 43119 43865 43568 34922 47638>,
			<43144 10222 41027 43014 43605 43530 46814 42275>,
			<43058  9299 41077 43132 43612 43535 42282 42242>,
			<43402  9582 41074 43424 43956 43530 41411 47786>,
			<44644 15013 40981 43799 43521 43548 42138 42154>,
			<44246 15233 40974 43231 44011 43536 42923 42472>,
			<41603 14464 41001 43212 43883 43538 41953 42298>,
			<41853 14753 41177 43205 43151 43624 41791 42307>,
			<41263 14685 41166 43200 43079 43634 41526 47627>,
			<42904 15930 41208 43113 43223 43961 41551 47658>,
			<42058 16276 41109 43100 43172 43605 41072 47769>,
			<47652 15532 41115 43107 43850 43594 41204 42350>,
			<47254 15424 41096 43066 43825 43628 41090 42397>,
			<47427 15697 41148 43207 43821 43551 41064 42055>,
			<49142 13302 41121 43014 43890 43629 48005 42453>,
			<48544 12771 41813 43098 43450 43641 48671 47705>,
			<45586 13914 41821 43043 43363 43523 41686 48096>,
			<45263 13353 41819 43200 43360 43532 44204 48053>,
			<46777  2797 41796 43059 43462 43522 45009 47697>,
			<46955  2225 41819 43447 43053 43539 44258 47616>,
			<46532  3753 41822 43390 44004 43541 42642 47854>,
			<35766  3921 41814 43483 44001 43575 41151 42355>,
			<34912  3418 41127 43430 44013 43583 41796 42287>,
			<36573   867 41139 43108 43926 43574 41437 42391>,
			<35983   365 41142 43039 43910 43546 42492 42069>,
			<36282  1623 41148 43029 43916 43537 47676 42056>;
	};
	qcom,bp-d-table-7 {
		qcom,temperature = <50>;
		qcom,nrows = <35>;
		qcom,ncols = <8>;
		qcom,conv-factor = <10000 10000 10000 10000 10000 100000 100000 10000>;
		qcom,data = <43690 56263 41020  6708 21845 43710 43680 21845>,
			<43705 57228 41020 61820 21845 43571 43093 21845>,
			<43661 53959 41020 45222 21845 43601 44878 21845>,
			<43664 53337 41023 44102 44533 43965 41503 45501>,
			<43748 54877 41004 44936 44902 43950 41250 48575>,
			<43723 54291 41155 43378 44570 43594 42227 48875>,
			<43554 11064 41088 43046 43322 43568 47412 48066>,
			<43625 11789 41121 43239 43410 43580 45236 47667>,
			<43918  8888 41798 43160 43399 43574 35780 47847>,
			<43824  8252 41855 43138 43136 43528 35278 42417>,
			<43144  9821 41834 43185 43947 43522 35774 42862>,
			<43058  9223 41756 43161 43638 43522 47921 42782>,
			<43402  9533 41758 43067 43588 43534 42779 42114>,
			<44644  9549 41737 44020 43578 43619 47707 42751>,
			<44246 14941 41786 43891 43915 43641 41347 42994>,
			<41603 15188 41769 43194 44029 43644 42663 42770>,
			<41853 14452 41945 43849 43883 43587 41944 42877>,
			<41263 14709 41921 43141 43152 44012 41479 42015>,
			<42904 15873 41928 43061 43166 43909 41409 42405>,
			<42058 16381 41982 43215 43150 43945 41563 42003>,
			<47652 15536 41952 43249 43807 43591 41765 42139>,
			<47254 15447 41962 43245 43930 43635 42996 42812>,
			<47427 12966 41887 43860 43905 43643 42953 42909>,
			<49142 13249 41880 43199 43791 43647 42472 42855>,
			<48544 12774 41882 43138 43094 43641 42409 42371>,
			<45586 13889 41868 43900 43308 43626 44255 42433>,
			<45263 13345 41867 43844 43466 43618 44839 42442>,
			<46777  2792 41909 43065 43209 43599 44067 42419>,
			<46955  2233 41909 43429 43997 43632 41496 42015>,
			<46532  3755 41866 43450 43951 43526 42708 42233>,
			<35766  3920 41867 43104 43638 43575 42107 42824>,
			<34912  3399 41869 43215 43639 43528 42003 42961>,
			<36573   875 41861 43194 43610 43547 42804 42910>,
			<35983   275 41884 43898 43955 43619 41446 42917>,
			<36282  1607 41875 43795 43907 43645 41215 42938>;
	};
};
